VERSION ""

NS_ :

BS_:

BU_: ADASM GatewayA

BO_ 517 MSG_RealSpeed: 2 GatewayA
 SG_ SIG_VehicleSpeed : 8|8@1+ (1,0) [0|250] "km/h"  ADASM
 SG_ SIG_Depending : 0|8@1+ (1,0) [0|255] ""  ADASM

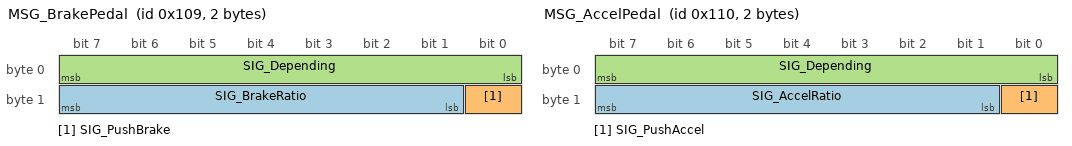
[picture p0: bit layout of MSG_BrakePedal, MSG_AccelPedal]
BO_ 265 MSG_BrakePedal: 2 GatewayA
 SG_ SIG_BrakeRatio : 9|7@1+ (1,0) [0|100] "%"  ADASM
 SG_ SIG_PushBrake : 8|1@1+ (1,0) [0|1] ""  ADASM
 SG_ SIG_Depending : 0|8@1+ (1,0) [0|255] ""  ADASM

BO_ 272 MSG_AccelPedal: 2 GatewayA
 SG_ SIG_AccelRatio : 9|7@1+ (1,0) [0|100] "%"  ADASM
 SG_ SIG_PushAccel : 8|1@1+ (1,0) [0|1] ""  ADASM
 SG_ SIG_Depending : 0|8@1+ (1,0) [0|255] ""  ADASM
